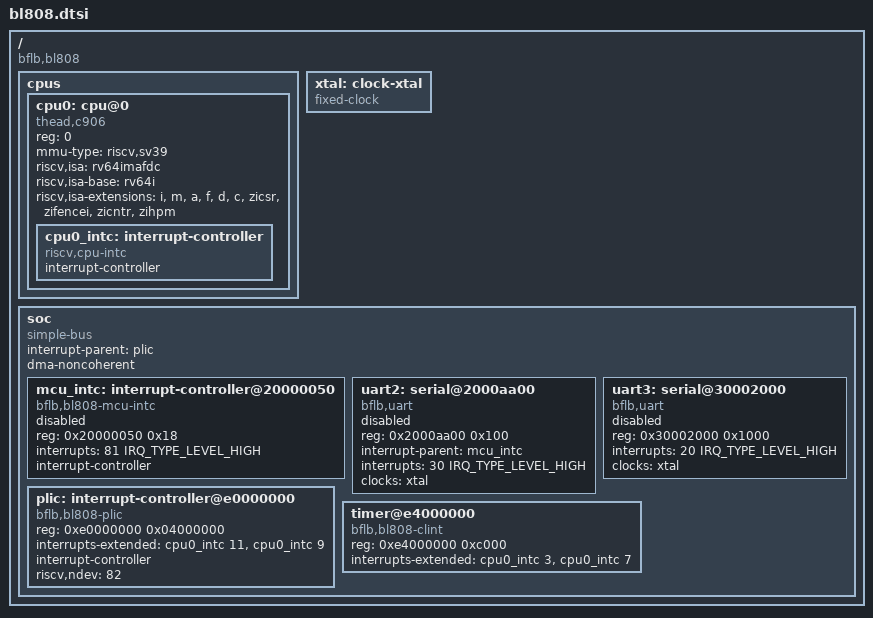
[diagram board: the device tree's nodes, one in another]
// SPDX-License-Identifier: (GPL-2.0+ OR MIT)

#include <dt-bindings/interrupt-controller/irq.h>

/ {
	compatible = "bflb,bl808";
	#address-cells = <1>;
	#size-cells = <1>;

	cpus {
		#address-cells = <1>;
		#size-cells = <0>;

		cpu0: cpu@0 {
			compatible = "thead,c906", "riscv";
			device_type = "cpu";
			reg = <0>;
			mmu-type = "riscv,sv39";
			riscv,isa = "rv64imafdc";
			riscv,isa-base = "rv64i";
			riscv,isa-extensions = "i", "m", "a", "f", "d", "c",
					       "zicsr", "zifencei", "zicntr", "zihpm";

			cpu0_intc: interrupt-controller {
				compatible = "riscv,cpu-intc";
				interrupt-controller;
				#address-cells = <0>;
				#interrupt-cells = <1>;
			};
		};
	};

	xtal: clock-xtal {
		compatible = "fixed-clock";
		#clock-cells = <0>;
	};

	soc {
		compatible = "simple-bus";
		#address-cells = <1>;
		#size-cells = <1>;
		ranges;
		interrupt-parent = <&plic>;
		dma-noncoherent;

		mcu_intc: interrupt-controller@20000050 {
			compatible = "bflb,bl808-mcu-intc";
			reg = <0x20000050 0x18>;
			interrupts = <81 IRQ_TYPE_LEVEL_HIGH>;
			interrupt-controller;
			#address-cells = <0>;
			#interrupt-cells = <2>;
			status = "disabled";
		};

		uart2: serial@2000aa00 {
			compatible = "bflb,uart";
			reg = <0x2000aa00 0x100>;
			interrupt-parent = <&mcu_intc>;
			interrupts = <30 IRQ_TYPE_LEVEL_HIGH>;
			clocks = <&xtal>;
			clock-names = "baud";
			status = "disabled";
		};

		uart3: serial@30002000 {
			compatible = "bflb,uart";
			reg = <0x30002000 0x1000>;
			interrupts = <20 IRQ_TYPE_LEVEL_HIGH>;
			clocks = <&xtal>;
			clock-names = "baud";
			status = "disabled";
		};

		plic: interrupt-controller@e0000000 {
			compatible = "bflb,bl808-plic", "thead,c900-plic";
			reg = <0xe0000000 0x04000000>;
			interrupts-extended = <&cpu0_intc 11>, <&cpu0_intc 9>;
			interrupt-controller;
			#address-cells = <0>;
			#interrupt-cells = <2>;
			riscv,ndev = <82>;
		};

		timer@e4000000 {
			compatible = "bflb,bl808-clint", "thead,c900-clint";
			reg = <0xe4000000 0xc000>;
			interrupts-extended = <&cpu0_intc 3>, <&cpu0_intc 7>;
		};
	};
};
